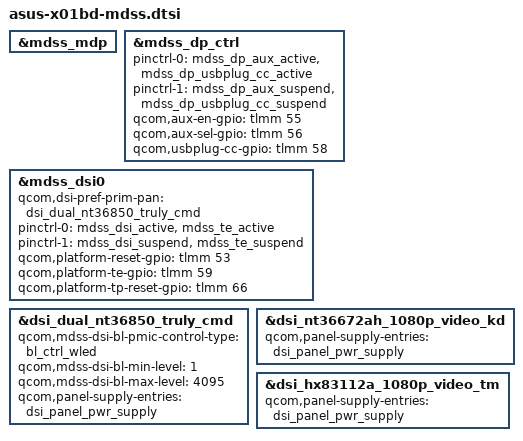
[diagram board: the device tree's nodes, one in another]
// SPDX-License-Identifier: GPL-2.0
// Copyright (C) 2021 Atom-X-Devs < https://www.github.com/Atom-X-Devs >

&mdss_mdp {
	#include "display/dsi-panel-hx83112a-1080p-video-tm.dts"
	#include "display/dsi-panel-nt36672ah-1080p-video-kd.dtsi"
};

&mdss_dp_ctrl {
	pinctrl-names = "mdss_dp_active", "mdss_dp_sleep";
	pinctrl-0 = <&mdss_dp_aux_active &mdss_dp_usbplug_cc_active>;
	pinctrl-1 = <&mdss_dp_aux_suspend &mdss_dp_usbplug_cc_suspend>;
	qcom,aux-en-gpio = <&tlmm 55 0>;
	qcom,aux-sel-gpio = <&tlmm 56 0>;
	qcom,usbplug-cc-gpio = <&tlmm 58 0>;
};

&mdss_dsi0 {
	qcom,dsi-pref-prim-pan = <&dsi_dual_nt36850_truly_cmd>;
	pinctrl-names = "mdss_default", "mdss_sleep";
	pinctrl-0 = <&mdss_dsi_active &mdss_te_active>;
	pinctrl-1 = <&mdss_dsi_suspend &mdss_te_suspend>;
	qcom,platform-reset-gpio = <&tlmm 53 0>;
	qcom,platform-te-gpio = <&tlmm 59 0>;
	qcom,platform-tp-reset-gpio = <&tlmm 66 0>;
};

&dsi_dual_nt36850_truly_cmd {
	qcom,mdss-dsi-bl-pmic-control-type = "bl_ctrl_wled";
	qcom,mdss-dsi-bl-min-level = <1>;
	qcom,mdss-dsi-bl-max-level = <4095>;
	qcom,panel-supply-entries = <&dsi_panel_pwr_supply>;
};

&dsi_nt36672ah_1080p_video_kd {
	  qcom,panel-supply-entries = <&dsi_panel_pwr_supply>;
};

&dsi_hx83112a_1080p_video_tm {
	  qcom,panel-supply-entries = <&dsi_panel_pwr_supply>;
};
